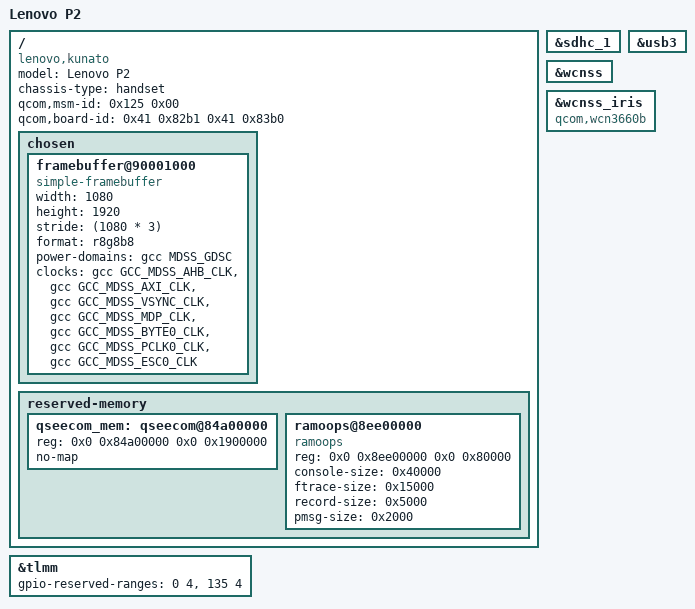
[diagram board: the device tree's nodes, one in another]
// SPDX-License-Identifier: GPL-2.0-only

/dts-v1/;

#include "msm8953.dtsi"

/delete-node/ &qseecom_mem;

/ {
 	model = "Lenovo P2";
 	compatible = "lenovo,kunato", "qcom,msm8953";
	chassis-type = "handset";
	qcom,msm-id = <0x125 0x00>;
	qcom,board-id = <0x41 0x82b1 0x41 0x83b0>;

	chosen {
		#address-cells = <2>;
		#size-cells = <2>;
		ranges;

		framebuffer@90001000 {
			compatible = "simple-framebuffer";

			width = <1080>;
			height = <1920>;
			stride = <(1080 * 3)>;
			format = "r8g8b8";

			power-domains = <&gcc MDSS_GDSC>;

			clocks = <&gcc GCC_MDSS_AHB_CLK>,
				 <&gcc GCC_MDSS_AXI_CLK>,
				 <&gcc GCC_MDSS_VSYNC_CLK>,
				 <&gcc GCC_MDSS_MDP_CLK>,
				 <&gcc GCC_MDSS_BYTE0_CLK>,
				 <&gcc GCC_MDSS_PCLK0_CLK>,
				 <&gcc GCC_MDSS_ESC0_CLK>;
		};
	};

	reserved-memory {
		qseecom_mem: qseecom@84a00000 {
			reg = <0x0 0x84a00000 0x0 0x1900000>;
			no-map;
		};

		ramoops@8ee00000 {
			compatible = "ramoops";
			reg = <0x0 0x8ee00000 0x0 0x80000>;
			console-size = <0x40000>;
			ftrace-size = <0x15000>;
			record-size = <0x5000>;
			pmsg-size = <0x2000>;
		};
	};
};

&sdhc_1 {
	status = "okay";
};

&usb3 {
	status = "okay";
};

&tlmm {
	gpio-reserved-ranges = <0 4>, <135 4>;
};

&wcnss {
	status = "okay";
};

&wcnss_iris {
	compatible = "qcom,wcn3660b";
	status = "okay";
};
